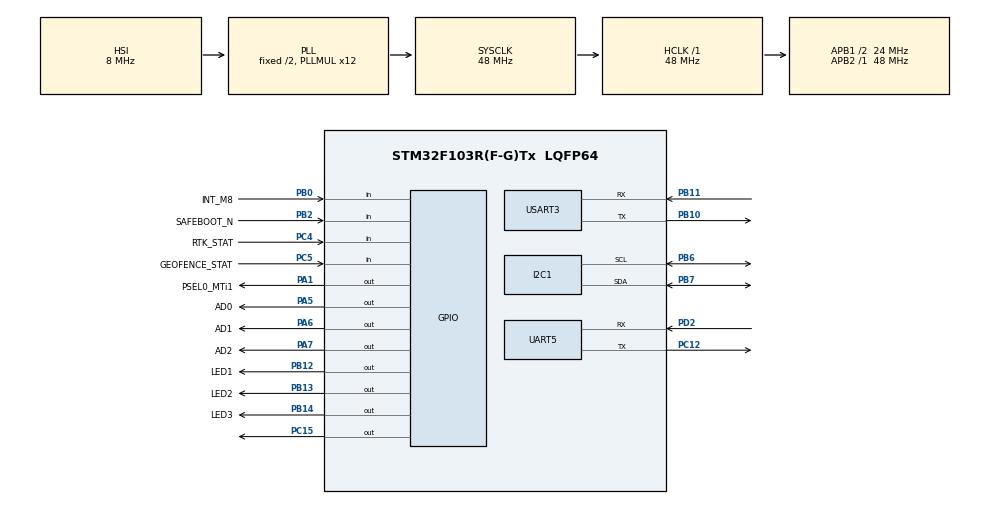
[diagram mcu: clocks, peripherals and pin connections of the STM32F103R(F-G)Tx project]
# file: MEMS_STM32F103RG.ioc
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Mcu.Family=STM32F1
Mcu.Name=STM32F103R(F-G)Tx
Mcu.Package=LQFP64
NVIC.PriorityGroup=NVIC_PRIORITYGROUP_4
NVIC.TIM1_UP_TIM10_IRQn=true\:0\:0\:false\:false\:true\:false
NVIC.TIM3_IRQn=true\:0\:0\:false\:false\:true\:true
NVIC.TimeBase=TIM1_UP_TIM10_IRQn
NVIC.TimeBaseIP=TIM1
NVIC.UART5_IRQn=true\:0\:0\:false\:true\:true\:5\:true
NVIC.USART3_IRQn=true\:0\:0\:false\:true\:true\:4\:true
PA1.GPIO_Label=PSEL0_MTi1
PA1.PinState=GPIO_PIN_SET
PA1.Signal=GPIO_Output
PA13.Mode=Serial_Wire
PA13.Signal=SYS_JTMS-SWDIO
PA14.Mode=Serial_Wire
PA14.Signal=SYS_JTCK-SWCLK
PA5.GPIO_Label=AD0
PA5.Signal=GPIO_Output
PA6.GPIO_Label=AD1
PA6.Signal=GPIO_Output
PA7.GPIO_Label=AD2
PA7.Signal=GPIO_Output
PB0.GPIO_Label=INT_M8
PB0.Signal=GPIO_Input
PB1.Signal=S_TIM3_CH4
PB10.Mode=Asynchronous
PB10.Signal=USART3_TX
PB11.Mode=Asynchronous
PB11.Signal=USART3_RX
PB12.GPIO_Label=LED1
PB12.PinState=GPIO_PIN_SET
PB12.Signal=GPIO_Output
PB13.GPIO_Label=LED2
PB13.PinState=GPIO_PIN_SET
PB13.Signal=GPIO_Output
PB14.GPIO_Label=LED3
PB14.PinState=GPIO_PIN_SET
PB14.Signal=GPIO_Output
PB2.GPIO_Label=SAFEBOOT_N
PB2.Signal=GPIO_Input
PB6.Mode=I2C
PB6.Signal=I2C1_SCL
PB7.Mode=I2C
PB7.Signal=I2C1_SDA
PC12.Mode=Asynchronous
PC12.Signal=UART5_TX
PC15-OSC32_OUT.Signal=GPIO_Output
PC4.GPIO_Label=RTK_STAT
PC4.Signal=GPIO_Input
PC5.GPIO_Label=GEOFENCE_STAT
PC5.Signal=GPIO_Input
PD0-OSC_IN.Signal=RCC_OSC_IN
PD1-OSC_OUT.Signal=RCC_OSC_OUT
PD2.Mode=Asynchronous
PD2.Signal=UART5_RX
ProjectManager.HeapSize=0x200
ProjectManager.StackSize=0x400
ProjectManager.TargetToolchain=MDK-ARM V5
RCC.AHBFreq_Value=48000000
RCC.APB1CLKDivider=RCC_HCLK_DIV2
RCC.APB1Freq_Value=24000000
RCC.APB1TimFreq_Value=48000000
RCC.APB2Freq_Value=48000000
RCC.APB2TimFreq_Value=48000000
RCC.HCLKFreq_Value=48000000
RCC.HSEDivPLL=RCC_HSE_PREDIV_DIV2
RCC.HSE_VALUE=12000000
RCC.PLLMUL=RCC_PLL_MUL12
RCC.SYSCLKFreq_VALUE=48000000
RCC.SYSCLKSource=RCC_SYSCLKSOURCE_PLLCLK
RCC.USBFreq_Value=48000000
SH.S_TIM3_CH4.0=TIM3_CH4
TIM3.Channel-Input_Capture3_from_TRC=TIM_CHANNEL_3
UART5.VirtualMode=Asynchronous
USART3.VirtualMode=VM_ASYNC
VP_SYS_VS_tim1.Mode=TIM1
VP_TIM3_VS_CH3.Mode=Input_Capture3_from_TRC
VP_TIM3_VS_ClockSourceINT.Mode=Internal
VP_TIM3_VS_ClockSourceITR.Mode=TriggerSource_ITR0
board=MEMS_STM32F103RG

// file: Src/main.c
/**
  ******************************************************************************
  * @file           : main.c
  * @brief          : Main program body
  ******************************************************************************
  ** This notice applies to any and all portions of this file
  * that are not between comment pairs USER CODE BEGIN and
  * USER CODE END. Other portions of this file, whether
  * inserted by the user or by software development tools
  * are owned by their respective copyright owners.
  *
  * COPYRIGHT(c) 2018 STMicroelectronics
  *
  * Redistribution and use in source and binary forms, with or without modification,
  * are permitted provided that the following conditions are met:
  *   1. Redistributions of source code must retain the above copyright notice,
  *      this list of conditions and the following disclaimer.
  *   2. Redistributions in binary form must reproduce the above copyright notice,
  *      this list of conditions and the following disclaimer in the documentation
  *      and/or other materials provided with the distribution.
  *   3. Neither the name of STMicroelectronics nor the names of its contributors
  *      may be used to endorse or promote products derived from this software
  *      without specific prior written permission.
  *
  * THIS SOFTWARE IS PROVIDED BY THE COPYRIGHT HOLDERS AND CONTRIBUTORS "AS IS"
  * AND ANY EXPRESS OR IMPLIED WARRANTIES, INCLUDING, BUT NOT LIMITED TO, THE
  * IMPLIED WARRANTIES OF MERCHANTABILITY AND FITNESS FOR A PARTICULAR PURPOSE ARE
  * DISCLAIMED. IN NO EVENT SHALL THE COPYRIGHT HOLDER OR CONTRIBUTORS BE LIABLE
  * FOR ANY DIRECT, INDIRECT, INCIDENTAL, SPECIAL, EXEMPLARY, OR CONSEQUENTIAL
  * DAMAGES (INCLUDING, BUT NOT LIMITED TO, PROCUREMENT OF SUBSTITUTE GOODS OR
  * SERVICES; LOSS OF USE, DATA, OR PROFITS; OR BUSINESS INTERRUPTION) HOWEVER
  * CAUSED AND ON ANY THEORY OF LIABILITY, WHETHER IN CONTRACT, STRICT LIABILITY,
  * OR TORT (INCLUDING NEGLIGENCE OR OTHERWISE) ARISING IN ANY WAY OUT OF THE USE
  * OF THIS SOFTWARE, EVEN IF ADVISED OF THE POSSIBILITY OF SUCH DAMAGE.
  *
  ******************************************************************************
  */
#include "main.h"
#include "stm32f1xx_hal.h"
#include "i2c.h"
#include "tim.h"
#include "usart.h"
#include "gpio.h"

/* USER CODE BEGIN PV */
/* Private variables ---------------------------------------------------------*/

/* USER CODE END PV */

void SystemClock_Config(void);
static void MX_NVIC_Init(void);

/* USER CODE BEGIN PFP */
/* Private function prototypes -----------------------------------------------*/

/* USER CODE END PFP */

int main(void)
{

  /* MCU Configuration----------------------------------------------------------*/

  /* Reset of all peripherals, Initializes the Flash interface and the Systick. */
  HAL_Init();

  /* Configure the system clock */
  SystemClock_Config();

  /* Initialize all configured peripherals */
  MX_GPIO_Init();
  MX_USART3_UART_Init();
  MX_UART5_Init();
  MX_TIM3_Init();
  MX_I2C1_Init();

  /* Initialize interrupts */
  MX_NVIC_Init();

  /* Infinite loop */
  /* USER CODE BEGIN WHILE */
	Init_MTi_i2C();
	HAL_TIM_Base_Start_IT(&htim3);
  while (1)
  {

  /* USER CODE END WHILE */

  }

}

void SystemClock_Config(void)
{

  RCC_OscInitTypeDef RCC_OscInitStruct;
  RCC_ClkInitTypeDef RCC_ClkInitStruct;

    /**Initializes the CPU, AHB and APB busses clocks
    */
  RCC_OscInitStruct.OscillatorType = RCC_OSCILLATORTYPE_HSI;
  RCC_OscInitStruct.HSIState = RCC_HSI_ON;
  RCC_OscInitStruct.HSICalibrationValue = 16;
  RCC_OscInitStruct.PLL.PLLState = RCC_PLL_ON;
  RCC_OscInitStruct.PLL.PLLSource = RCC_PLLSOURCE_HSI_DIV2;
  RCC_OscInitStruct.PLL.PLLMUL = RCC_PLL_MUL12;
  if (HAL_RCC_OscConfig(&RCC_OscInitStruct) != HAL_OK)
  {
    _Error_Handler(__FILE__, __LINE__);
  }

    /**Initializes the CPU, AHB and APB busses clocks
    */
  RCC_ClkInitStruct.ClockType = RCC_CLOCKTYPE_HCLK|RCC_CLOCKTYPE_SYSCLK
                              |RCC_CLOCKTYPE_PCLK1|RCC_CLOCKTYPE_PCLK2;
  RCC_ClkInitStruct.SYSCLKSource = RCC_SYSCLKSOURCE_PLLCLK;
  RCC_ClkInitStruct.AHBCLKDivider = RCC_SYSCLK_DIV1;
  RCC_ClkInitStruct.APB1CLKDivider = RCC_HCLK_DIV2;
  RCC_ClkInitStruct.APB2CLKDivider = RCC_HCLK_DIV1;

  if (HAL_RCC_ClockConfig(&RCC_ClkInitStruct, FLASH_LATENCY_1) != HAL_OK)
  {
    _Error_Handler(__FILE__, __LINE__);
  }

    /**Configure the Systick interrupt time
    */
  HAL_SYSTICK_Config(HAL_RCC_GetHCLKFreq()/1000);

    /**Configure the Systick
    */
  HAL_SYSTICK_CLKSourceConfig(SYSTICK_CLKSOURCE_HCLK);

  /* SysTick_IRQn interrupt configuration */
  HAL_NVIC_SetPriority(SysTick_IRQn, 0, 0);
}

/**
  * @brief NVIC Configuration.
  * @retval None
  */
static void MX_NVIC_Init(void)
{
  /* USART3_IRQn interrupt configuration */
  HAL_NVIC_SetPriority(USART3_IRQn, 0, 0);
  HAL_NVIC_EnableIRQ(USART3_IRQn);
  /* UART5_IRQn interrupt configuration */
  HAL_NVIC_SetPriority(UART5_IRQn, 0, 0);
  HAL_NVIC_EnableIRQ(UART5_IRQn);
}

//void HAL_TIM_PeriodElapsedCallback(TIM_HandleTypeDef *htim)
//{
//  /* USER CODE BEGIN Callback 0 */

//  /* USER CODE END Callback 0 */
//  if (htim->Instance == TIM1) {
//    HAL_IncTick();
//  }
//  /* USER CODE BEGIN Callback 1 */

//  /* USER CODE END Callback 1 */
//}

void _Error_Handler(char *file, int line)
{
  while(1)
  {
  }
}

/************************ (C) COPYRIGHT STMicroelectronics *****END OF FILE****/
